# M0519AE_v1 register map
File version: 1.0
M0519AE_v1 SVD file
Registers are 32-bit, read-write, reset 0x0 unless marked. A register's access mark holds for its fields unless they carry their own. Offsets are from the block's base; lines under a group give offsets from that group; [hi:lo] are bit positions; {n}, {i} and the like mark numbered series; 'fields as' and 'values as' point back to an identical list; <NAME> marks a mode.

## Memory map
0x40004000 WDT size 0x8 — WDT Register Map
0x40004100 WWDT size 0x10 — WWDT Register Map
0x40010000 TMR01 blocks up to offset 0x3C — TMR Register Map
0x40020000 I2C0 blocks up to offset 0x44 — I2C Register Map
0x40030000 SPI0 blocks up to offset 0x48 — SPI Register Map
0x40034000 SPI1 blocks up to offset 0x48 — SPI Register Map
0x40040000 BPWM0 blocks up to offset 0x80 — BPWM0 Register Map
0x40050000 UART0 size 0x3C — UART Register Map
0x400D0000 ACMP size 0x10 — ACMP Register Map
0x400E0000 EADC blocks up to offset 0x164 — EADC Register Map
0x400F0000 OPA size 0x8 — OPA Register Map
0x40110000 TMR23 blocks up to offset 0x3C — TMR Register Map
0x40130000 SPI2 blocks up to offset 0x48 — SPI Register Map
0x40150000 UART1 size 0x3C — UART Register Map
0x40190000 EPWM0 blocks up to offset 0x44 — EPWM Register Map
0x40194000 EPWM1 blocks up to offset 0x44 — EPWM Register Map
0x401B0000 ECAP0 size 0x20 — ECAP Register Map
0x401B4000 ECAP1 size 0x20 — ECAP Register Map
0x50000000 GCR blocks up to offset 0x104 — GCR Register Map
0x50000200 CLK size 0x28 — CLK Register Map
0x50000300 INT blocks up to offset 0x8C — INT Register Map
0x50004000 GPIO blocks up to offset 0x448 — GPIO Register Map
0x5000C000 FMC blocks up to offset 0x44 — FMC Register Map
0x50014000 HDIV blocks up to offset 0x18 — HDIV Register Map
0xE000E010 SYST size 0xC — SYST Register Map
0xE000E100 NVIC blocks up to offset 0x320 — NVIC Register Map
0xE000ED00 SCB blocks up to offset 0x24 — SCB Register Map

## SYST — SYST Register Map
Base 0xE000E010
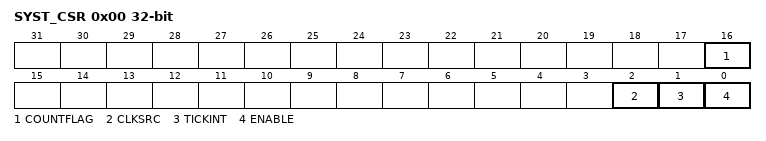
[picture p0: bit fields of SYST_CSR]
0x00 SYST_CSR — SysTick Control and Status Register
  [16] COUNTFLAG — System Tick Counter Flag. Returns 1 if timer counted to 0 since last time this register was read. COUNTFLAG is set by a count transition from 1 to 0. COUNTFLAG is cleared on read or by a write to the Current Value register (SYST_CVR).
  [2] CLKSRC — System Tick Clock Source Selection
    0=Clock source is optional, refer to STCLK_S (CLKSEL0[5:3]); 1=Core clock used for SysTick timer
  [1] TICKINT — System Tick Interrupt Enabled
    0=Counting down to 0 does not cause the SysTick exception to be pended. Software can use COUNTFLAG to determine if a count to 0 has occurred; 1=Counting down to 0 will cause the SysTick exception to be pended. Clearing the SysTick Current Value register by a write in software will not cause SysTick to be pended
  [0] ENABLE — System Tick Counter Enable Bit
    0=SysTick counter Disabled; 1=SysTick counter Enabled
0x04 SYST_RVR reset not defined — SysTick Reload Value Register
  [23:0] RELOAD — System Tick Reload Value. Value to load into the Current Value register when the counter reaches 0.
0x08 SYST_CVR reset not defined — SysTick Current Value Register
  [23:0] CURRENT — System Tick Current Value. Current counter value. This is the value of the counter at the time it is sampled. The counter does not provide read-modify-write protection. The register is write-clear. A software write of any value will clear the register to 0.

## NVIC — NVIC Register Map
Base 0xE000E100
0x00 NVIC_ISER — IRQ0 ~ IRQ31 Set-enable Control Register
  [31:0] SETENA — Interrupt Enable Register. Enable one or more interrupts. Each bit represents an interrupt number from IRQ0 ~ IRQ31 (Vector number from 16 ~ 47). Write Operation: Note: Read value indicates the current enable status.
    0=No effect. Associated interrupt status Disabled; 1=Write 1 to enable associated interrupt. Associated interrupt status Enabled
0x80 NVIC_ICER — IRQ0 ~ IRQ31 Clear-enable Control Register
  [31:0] CLRENA — Interrupt Clear Enable Bits. Disable one or more interrupts. Each bit represents an interrupt number from IRQ0 ~ IRQ31 (Vector number from 16 ~ 47). Write Operation: Note: Read value indicates the current enable status.
    0=No effect. Associated interrupt status Disabled; 1=Write 1 to disable associated interrupt. Associated interrupt status Enabled
0x100 NVIC_ISPR — IRQ0 ~ IRQ31 Set-pending Control Register
  [31:0] SETPEND — Interrupt Set-pending. The ISPR forces interrupts into the pending state, and shows the interrupts that are pending. Each bit represents an IRQ number from IRQ0 ~ IRQ31 (Vector number from 16 ~ 47). Write Operation: Read value indicates the current pending status.
    0=No effect. Associated interrupt in not in pending status; 1=Write 1 to set pending state. Associated interrupt is in pending status
0x180 NVIC_ICPR — IRQ0 ~ IRQ31 Clear-pending Control Register
  [31:0] CLRPEND — Interrupt Clear-pending. The ICPR removes the pending state from interrupts, and shows the interrupts that are pending. Each bit represents an IRQ number from IRQ0 ~ IRQ31 (Vector number from 16 ~ 47). Write Operation: Read value indicates the current pending status.
    0=No effect. Associated interrupt in not in pending status; 1=Write 1 to clear pending state. Associated interrupt is in pending status
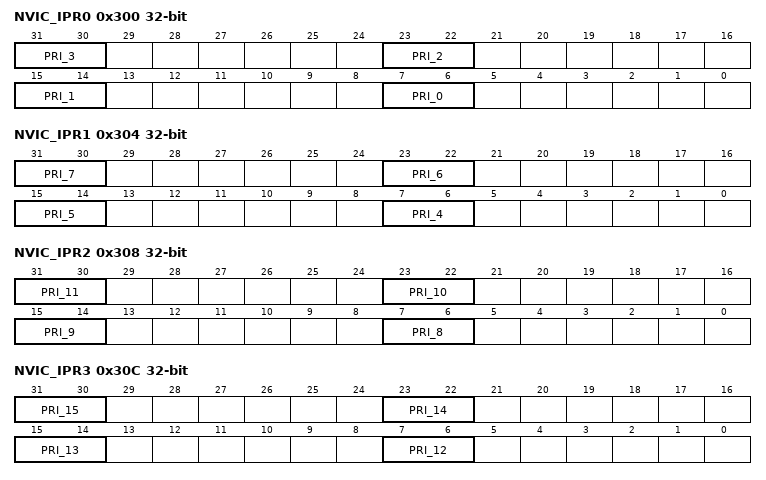
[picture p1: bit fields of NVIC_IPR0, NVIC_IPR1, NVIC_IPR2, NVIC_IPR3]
0x300 NVIC_IPR0 — IRQ0 ~ IRQ3 Interrupt Priority Control Register
  [8n+7:8n+6] PRI_{n} (n=0..3) — Priority of IRQ{n} "0" denotes the highest priority and "3" denotes lowest priority.
0x304 NVIC_IPR1 — IRQ4 ~ IRQ7 Interrupt Priority Control Register
  [8n-25:8n-26] PRI_{n} (n=4..7) — Priority of IRQ{n} "0" denotes the highest priority and "3" denotes lowest priority.
0x308 NVIC_IPR2 — IRQ8 ~ IRQ11 Interrupt Priority Control Register
  [8n-57:8n-58] PRI_{n} (n=8..11) — Priority of IRQ{n} "0" denotes the highest priority and "3" denotes lowest priority.
0x30C NVIC_IPR3 — IRQ12 ~ IRQ15 Interrupt Priority Control Register
  [8n-89:8n-90] PRI_{n} (n=12..15) — Priority of IRQ{n} "0" denotes the highest priority and "3" denotes lowest priority.
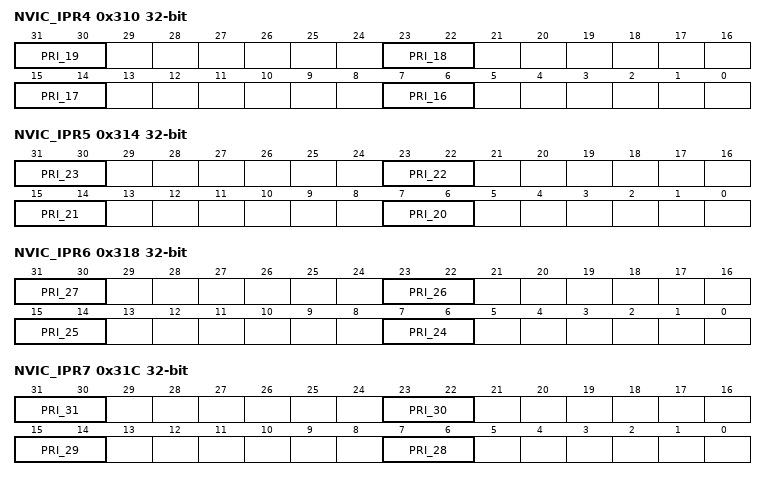
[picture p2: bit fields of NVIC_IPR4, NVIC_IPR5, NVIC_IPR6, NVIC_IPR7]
0x310 NVIC_IPR4 — IRQ16 ~ IRQ19 Interrupt Priority Control Register
  [8n-121:8n-122] PRI_{n} (n=16..19) — Priority of IRQ{n} "0" denotes the highest priority and "3" denotes lowest priority.
0x314 NVIC_IPR5 — IRQ20 ~ IRQ23 Interrupt Priority Control Register
  [8n-153:8n-154] PRI_{n} (n=20..23) — Priority of IRQ{n} "0" denotes the highest priority and "3" denotes lowest priority.
0x318 NVIC_IPR6 — IRQ24 ~ IRQ27 Interrupt Priority Control Register
  [8n-185:8n-186] PRI_{n} (n=24..27) — Priority of IRQ{n} "0" denotes the highest priority and "3" denotes lowest priority.
0x31C NVIC_IPR7 — IRQ28 ~ IRQ31 Interrupt Priority Control Register
  [8n-217:8n-218] PRI_{n} (n=28..31) — Priority of IRQ{n} "0" denotes the highest priority and "3" denotes lowest priority.
